# YTM32B1LE1 register map
Vendor: YTMicro; File version: 1.0
CPU: CM0PLUS r0p1, little endian, MPU, FPU, 2 interrupt priority bits
Registers are 32-bit, read-write, reset 0x0 unless marked. A register's access mark holds for its fields unless they carry their own. Offsets are from the block's base; [hi:lo] are bit positions; {n}, {i} and the like mark numbered series; 'fields as' and 'values as' point back to an identical list.

## eTMR0 — Enhanced timer
Base 0x40038000; register names take the prefix eTMR0_
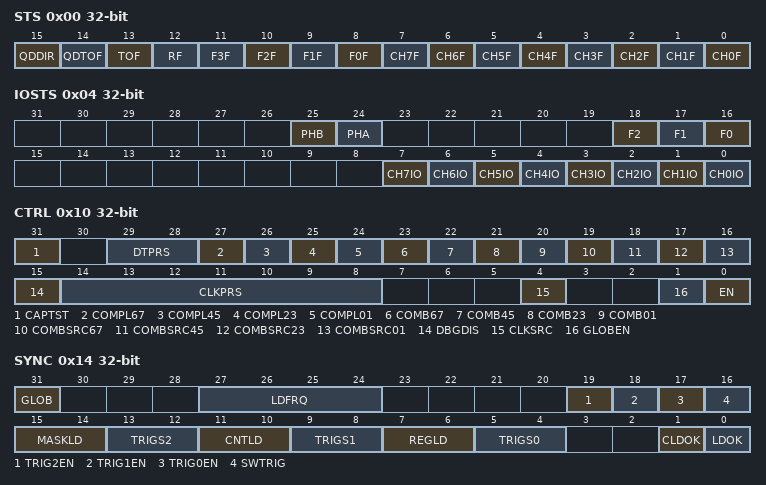
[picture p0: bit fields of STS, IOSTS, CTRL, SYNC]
0x00 STS
  [15] QDDIR ro — Indicate quadrature decoder counter direction.
    0=Quadrature counter increase; 1=Quadrature counter decrease
  [14] QDTOF — When STS[QDDIR]=0, STS[QDTOF]=1 means quadrature decoder counter increase from 0xFFFF to 0. When STS[QDDIR]=1, STS[QDTOF]=1 means quadrature decoder counter decrease from 0 to oxFFFF. Write 1 to clear the bit.
  [13] TOF — Timer overflow flag sets when counter increase from MOD[MOD] to 0. Write 1 to clear the bit.
  [12] RF — Reload flag sets when registers loading occurs. write 1 to clear the bit.
  [n+8] F{n}F (n=0..3) — Fault event {n} occurs flag. Write 1 to clear the bit.
  [n] CH{n}F (n=0..7) — Channel {n} flag is used for capture mode and compare mode. In capture mode, this flag sets when capture event occurs. In compare mode, this flag sets when counter matches the values. Write 1 to clear the bit.
0x04 IOSTS
  [25] PHB ro — Phase B input status is used for Quadrature Decoder. Read-only.
  [24] PHA ro — Phase A input status is used for Quadrature Decoder. Read-only.
  [18] F2 ro — Fault 2 input status is used for fault logic. Read-only.
  [17] F1 ro — Fault 1 input status is used for fault logic. Read-only.
  [16] F0 ro — Fault 0 input status is used for fault logic. Read-only.
  [n] CH{n}IO ro (n=0..7) — In capture mode, indicate channel {n} input status. In compare mode or PWM mode, indicate channel {n} output status. Read-only.
0x08 CNT
  [15:0] CNT — When CTRL[EN]=0, writing to this register initializes counter. When CTRL[EN]=1, reading this register gets the counter value, and writing to this register reloads value 0.
0x0C QDCNT
  [15:0] QDCNT ro — Reading this register gets quadrature decoder counter value. The write operation is not valid.
0x10 CTRL
  [31] CAPTST — This bit is used for the capture test.
    0=Capture test is disabled; 1=Capture test is enabled
  [29:28] DTPRS — Clock prescaler for deadtime counter.
    0=Deadtime clock prescaler is 1; 1=Deadtime clock prescaler is 2; 2=Deadtime clock prescaler is 4; 3=Deadtime clock prescaler is 8
  [27] COMPL67 — Channel 6 and 7 output independently or complementary in PWM mode.
    0=Independent mode; 1=Complementary mode
  [26] COMPL45 — Channel 4 and 5 output independently or complementary in PWM mode.
    0=Independent mode; 1=Complementary mode
  [25] COMPL23 — Channel 2 and 3 output independently or complementary in PWM mode.
    0=Independent mode; 1=Complementary mode
  [24] COMPL01 — Channel 0 and 1 output independently or complementary in PWM mode.
    0=Independent mode; 1=Complementary mode
  [23] COMB67 — Combination capture mode by channel 6 and 7.
    0=Combination capture mode is disabled; 1=Combination capture mode is enabled
  [22] COMB45 — Combination capture mode by channel 4 and 5.
    values as COMB67
  [21] COMB23 — Combination capture mode by channel 2 and 3.
    values as COMB67
  [20] COMB01 — Combination capture mode by channel 0 and 1.
    values as COMB67
  [19] COMBSRC67 — Combination capture mode input source from channel 6 or 7.
    0=Combination capture mode input source is channel 6; 1=Combination capture mode input source is channel 7
  [18] COMBSRC45 — Combination capture mode input source from channel 4 or 5.
    0=Combination capture mode input source is channel 4; 1=Combination capture mode input source is channel 5
  [17] COMBSRC23 — Combination capture mode input source from channel 2 or 3.
    0=Combination capture mode input source is channel 2; 1=Combination capture mode input source is channel 3
  [16] COMBSRC01 — Combination capture mode input source from channel 0 or 1.
    0=Combination capture mode input source is channel 0; 1=Combination capture mode input source is channel 1
  [15] DBGDIS — Enable/disable the debug mode control.
    0=Counter stops under debug mode; 1=Counter keeps running under debug mode
  [14:8] CLKPRS — Clock prescaler for counter, from 1 to 128.
  [4] CLKSRC — Clock source for counter, bus clock or external clock.
    0=Select bus clock; 1=Select external clock
  [1] GLOBEN — eTMRs counter synchronization mechanisms.
    0=Global logic is disabled; 1=Global logic is enabled. When SYNC[GLOB]=1 from any eTMR includes itself, the counter starts running. When all eTMRs includes itself SYNC[GLOB]=0, the counter stops.
  [0] EN — eTMR enable/disable.
    0=The eTMR is disabled; 1=The eTMR is enabled
0x14 SYNC
  [31] GLOB — Generate global base signal. This bit is used to synchronize with other eTMRs which CTRL[GLOBEN]=1.
    0=Not generate global base signal; 1=Generate global base signal
  [27:24] LDFRQ — Registers Loading occurs at the reloading opportunity that meets this specified frequency.
  [19] TRIG2EN — Enable hardware trigger 2.
    0=Hardware trigger 2 is disabled; 1=Hardware trigger 2 is enabled
  [18] TRIG1EN — Enable hardware trigger 1.
    0=Hardware trigger 1 is disabled; 1=Hardware trigger 1 is enabled
  [17] TRIG0EN — Enable hardware trigger 0.
    0=Hardware trigger 0 is disabled; 1=Hardware trigger 0 is enabled
  [16] SWTRIG wo — Software trigger is used for relevant registers loading. Writing 1 to this bit generates one bus clock cycle pulse trigger. Write-only.
  [15:14] MASKLD — Select loading opportunity for CHMASK register.
    0=loading together with registers (MOD, CH_VAL0 and CH_VAL1); 1=Loading occurs when counter matches with MOD[MOD]; 2=Loading occurs with trigger event which selected by SYNC[TRIGS2]. Any valid hardware trigger x will generate a trigger event (x=0,1,2).
  [13:12] TRIGS2 — Select the loading trigger source for CHMASK register.
    0=Disable trigger; 1=Select software trigger; 2=Select hardware trigger; 3=Software and hardware trigger are both valid
  [11:10] CNTLD — Select loading opportunity for counter, the counter loads with value 0.
    0=loading together with registers (MOD, CH_VAL0 and CH_VAL1); 1=Loading occurs with trigger event which selected by SYNC[TRIGS1]. Any valid hardware trigger x will generate a trigger event (x=0,1,2).
  [9:8] TRIGS1 — Select the loading trigger source for counter.
    values as TRIGS2
  [7:6] REGLD — Select loading opportunity for registers (MOD, CH_VAL0, CH_VAL1).
    0=Loading is disabled; 1=Loading occurs when counter matches with MOD[MOD]; 2=Loading occurs with trigger event which selected by SYNC[TRIGS0]. Any valid hardware trigger x will generate a trigger event (x=0,1,2).
  [5:4] TRIGS0 — Select the loading trigger source for registers (MOD, CH_VAL0, CH_VAL1).
    values as TRIGS2
  [1] CLDOK — Write 1 to this bit to clear SYNC[LDOK], and it automatically clear when SYNC[LDOK]=0.
  [0] LDOK — Set LDOK=1 to indicate registers (MOD, CH_VAL0, CH_VAL1) loading is ready, it automatically clear when registers loading successfully.
    0=Registers loading is not ready; 1=Registers loading is ready and waits for loading opportunity
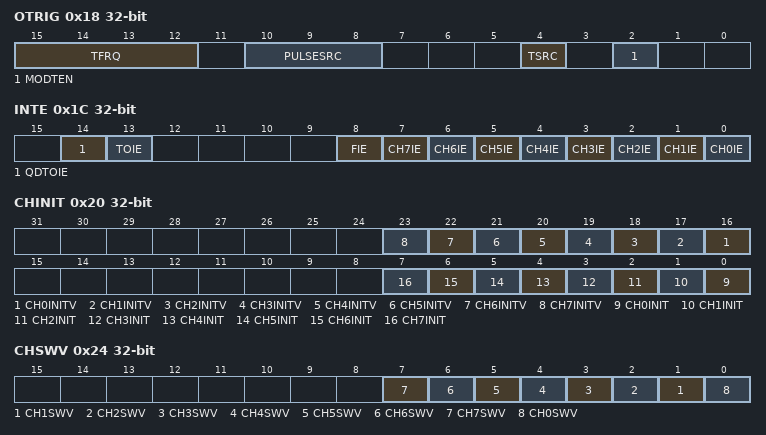
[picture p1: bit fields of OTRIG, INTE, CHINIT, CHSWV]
0x18 OTRIG
  [15:12] TFRQ — Trigger output occurs at the opportunity that meets the specified frequency.
  [10:8] PULSESRC — Select PWM as the pulse-out signal.
    {v}=Select channel {v} PWM as the pulse-out signal (v=0..6); 7=select channel 7 PWM as the pulse-out signal
  [4] TSRC — Trigger output source: matching event occurs or PWM output.
    0=Select trigger that generated by matching event; 1=Select PWM output as the trigger
  [2] MODTEN — Enable/disable the MOD[MOD] matching trigger.
    0=Not generate trigger when counter matches with MOD[MOD]; 1=Generate trigger when counter matches with MOD[MOD]
0x1C INTE
  [14] QDTOIE — Quadrature decoder timer overflow interrupt enable/disable.
    0=Quadrature decoder timer overflow interrupt is disabled; 1=Quadrature decoder timer overflow interrupt is enabled
  [13] TOIE — Timer overflow interrupt enable/disable.
    0=Timer overflow interrupt is disabled; 1=Timer overflow interrupt is enabled
  [8] FIE — Fault interrupt enable/disable.
    0=Fault interrupt is disabled; 1=Fault interrupt is enabled
  [n] CH{n}IE (n=0..7) — Channel {n} capture/compare interrupt enable/disable.
    0=Channel {n} interrupt is disabled; 1=Channel {n} interrupt is enabled
0x20 CHINIT
  [n+16] CH{n}INITV (n=0..7) — Channel {n} output initial value.
    0=Channel {n} output initial value is 0; 1=Channel {n} output initial value is 1
  [n] CH{n}INIT wo (n=0..7) — Write 1 to this bit to initialize channel output with CHINIT[CH{n}INITV], channel output change with a counter matching event. Write-Only.
    0=Channel {n} output is not initialized; 1=Channel {n} output is initialized
0x24 CHSWV
  [n] CH{n}SWV (n=1..7) — Channel {n} output value configured by software.
    0=Channel {n} output value forced to 0 by software; 1=Channel {n} output value forced to 1 by software
  [0] CH0SWV — Channel 0 forced value by software.
    0=Channel 0 output value forced to 0 by software; 1=Channel 0 output value forced to 1 by software
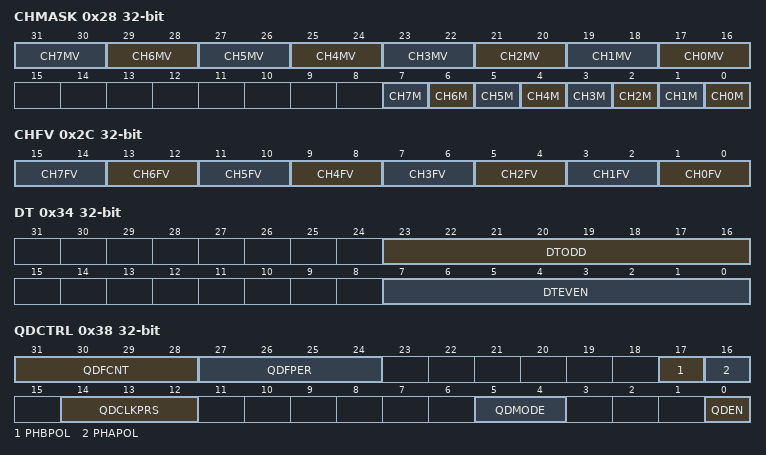
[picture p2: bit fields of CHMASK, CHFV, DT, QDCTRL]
0x28 CHMASK
  [2n+17:2n+16] CH{n}MV (n=0..7) — Define channel {n} output mask value, it's enabled when CHMASK[CH{n}M]=1.
    0=Channel {n} output mask value is 0; 1=Channel {n} output mask value is 1; 2=Channel {n} output mask value is tri-state; 3=Channel {n} output mask value is tri-state
  [n] CH{n}M (n=0..7) — Channel {n} output mask control used in PWM mode.
    0=Channel {n} output PWM normally; 1=Channel {n} output masked by CHMASK[CH{n}MV]
0x2C CHFV
  [2n+1:2n] CH{n}FV (n=0..7) — Channel {n} forced value when fault event occurs.
    0=Channel {n} output value forced to 0; 1=Channel {n} output value forced to 1; 2=Channel {n} output value forced to tri-state; 3=Channel {n} output value forced to tri-state
0x30 MOD reset 0xFFFF
  [15:0] MOD — Counter modulus value.
0x34 DT
  [23:16] DTODD — Define the deadtime value in odd channels output PWM.
  [7:0] DTEVEN — Define the deadtime value in even channels output PWM.
0x38 QDCTRL
  [31:28] QDFCNT — Quadrature decoder phase A and phase B input filter sample count, the input is ignored when its valid width was less than QDFCNT x QDFPER.
  [27:24] QDFPER — Quadrature decoder phase A and phase B input filter sample period, the input is ignored when its valid width was less than QDFCNT x QDFPER.
  [17] PHBPOL — Phase B polarity selection.
    0=Not invert phase B input; 1=Invert phase B input
  [16] PHAPOL — Phase A polarity selection.
    0=Not invert phase A input; 1=Invert phase A input
  [14:12] QDCLKPRS — Clock prescaler for quadrature decoder counter.
    0=Divided by 1; 1=Divided by 2; 2=Divided by 4; 3=Divided by 8; 4=Divided by 16; 5=Divided by 32; 6=Divided by 64; 7=Divided by 128
  [5:4] QDMODE — Select decoding mode in the quadrature decoder mode.
    0=Phase A and phase B decoding mode. When phase B changs follow phase A, the counter increases. When phase A changs follow phase B, the counter decreases.; 1=Phase A and phase B decoding mode. When phase A changs follow phase B, the counter increases. When phase B changs follow phase A, the counter decreases.; 2=Counting and direction decoding mode. Phase B input controls direction. When phase B input is high, the counter increases with phase A pulse. When phase B input is low, the counter decreases with phase A pulse.; 3=Counting and direction decoding mode. Phase A input controls direction. When phase A input is high, the counter increases with phase B pulse. When phase A input is low, the counter decreases with phase B pulse.
  [0] QDEN — Quadrature decoder enable/disable.
    0=Quadrature decoder is disabled; 1=Quadrature decoder is enabled
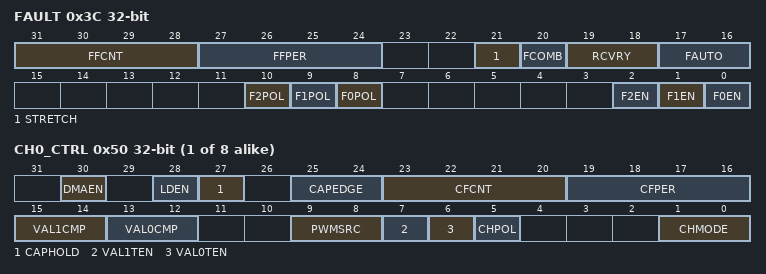
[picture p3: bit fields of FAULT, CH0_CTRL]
0x3C FAULT
  [31:28] FFCNT — Fault input filter sample count, the input is ignored when its valid width was less than FFCNT x FFPER.
  [27:24] FFPER — Fault input filter sample period, the input is ignored when its valid width was less than FFCNT x FFPER.
  [21] STRETCH — Fault input stretch to 2 bus clock cycles width at least.
  [20] FCOMB — When there is no bus clock, the fault event is generated by the combinational logic circuit.
    0=Fault combinational logic disable; 1=Fault combinational logic enable
  [19:18] RCVRY — Select PWM recovery opportunity after fault recovery.
    0=PWM recovery is disabled; 1=PWM recovers when counter matches with MOD[MOD]; 2=PWM recovers immediately
  [17:16] FAUTO — Select fault automatic recovery mode after the fault event end.
    0=After clearing STS[FxF] flag manually, the fault recovers automatically; 1=The fault recovers immediately, not care STS[FxF] flag; 2=The fault recovers immediately and STS[FxF] flag clear automatically
  [10] F2POL — Fault 2 input polarity selection.
    0=Not invert fault 2 input; 1=Invert fault 2 input
  [9] F1POL — Fault 1 input polarity selection.
    0=Not invert fault 1 input; 1=Invert fault 1 input
  [8] F0POL — Fault 0 input polarity selection.
    0=Not invert fault 0 input; 1=Invert fault 0 input
  [2] F2EN — Fault 2 enable.
    0=Fault 2 disable; 1=Fault 2 enbale
  [1] F1EN — Fault 1 enable.
    0=Fault 1 disable; 1=Fault 1 enbale
  [0] F0EN — Fault 0 enable.
    0=Fault 0 disable; 1=Fault 0 enbale
{0x50+0x20*i} CH{i}_CTRL (i=0..7)
  [30] DMAEN — DMA enable/disable for compare/capture mode.
    0=DMA is disabled; 1=DMA is enabled
  [28] LDEN — Current channel registers (CH_VAL0/CH_VAL1) loading enable/disable.
    0=Registers Loading is disabled; 1=Registers Loading is enabled
  [27] CAPHOLD — When capture hold is enabled and capture event has already occurred, the newly captured value do not overwrite the register CH_CVAL before register CH_CVAL reading operation and capture events are lost. After register CH_CVAL reading operation, the newly captured value will overwrite the register CH_CVAL. When capture hold is disabled, the newly captured value always overwrite to the register CH_CVAL.
    0=Capture hold is disabled; 1=Capture hold is enabled
  [25:24] CAPEDGE — Select the capture edge in the input capture mode.
    0=Capture is disabled; 1=Capture rising edge; 2=Capture falling edge; 3=Capture both rising edge and falling edge
  [23:20] CFCNT — Capture input filter sample counter, the input is ignored when its valid width was less than CFCNT x CFPER.
  [19:16] CFPER — Capture input filter sample period, the input is ignored when its valid width was less than CFCNT x CFPER.
  [15:14] VAL1CMP — Select the output value when counter matches with CH_VAL1[VAL1] in compare mode.
    0=Output value 0 when counter matches with CH_VAL1[VAL1]; 1=Output value 1 when counter matches with CH_VAL1[VAL1]; 2=Output toggle when counter matches with CH_VAL1[VAL1]
  [13:12] VAL0CMP — Select the output value when counter matches with CH_VAL0[VAL0] in compare mode.
    0=Output value 0 when counter matches with CH_VAL0[VAL0]; 1=Output value 1 when counter matches with CH_VAL0[VAL0]; 2=Output toggle when counter matches with CH_VAL0[VAL0]
  [9:8] PWMSRC — Select PWM source in PWM mode.
    0=Normal mode, PWM is generated by CH_VAL0[VAL0] and CH_VAL1[VAL1]; 1=Invert mode, invert the PWM in normal mode; 2=Software mode, PWM is generated by CHSWV register
  [7] VAL1TEN — Enable/disable generating trigger when counter matches with CH_VAL1[VAL1].
    0=Not generate trigger when counter matches with CH_VAL1[VAL1]; 1=Generate trigger when counter matches with CH_VAL1[VAL1]
  [6] VAL0TEN — Enable/disable generating trigger when counter matches with CH_VAL0[VAL0].
    0=Not generate trigger when counter matches with CH_VAL0[VAL0]; 1=Generate trigger when counter matches with CH_VAL0[VAL0]
  [5] CHPOL — Channel output polarity control.
    0=Not invert the channel output; 1=Invert the channel output
  [1:0] CHMODE — Select channel mode.
    0=Channel disable; 1=PWM mode; 2=Compare mode; 3=Capture mode
{0x54+0x20*i} CH{i}_VAL0 (i=0..7)
  [15:0] VAL0 — Define the value 0.
{0x58+0x20*i} CH{i}_VAL1 (i=0..7)
  [15:0] VAL1 — Define the value 1.
{0x5C+0x20*i} CH{i}_CVAL (i=0..7)
  [15:0] CVAL — In capture mode, store counter value when a capture event occurs.
